# FM33LG0XX register map
File version: 1.0
CPU: SC000 r1p0, little endian, no MPU, no FPU, 3 interrupt priority bits
Registers are 32-bit, read-write, reset 0x0 unless marked. A register's access mark holds for its fields unless they carry their own. Offsets are from the block's base; [hi:lo] are bit positions; {n}, {i} and the like mark numbered series.

## SPI0 — SPI0 module information
Base 0x40010400
Same registers: SPI1 0x40010800, SPI2 0x40014800
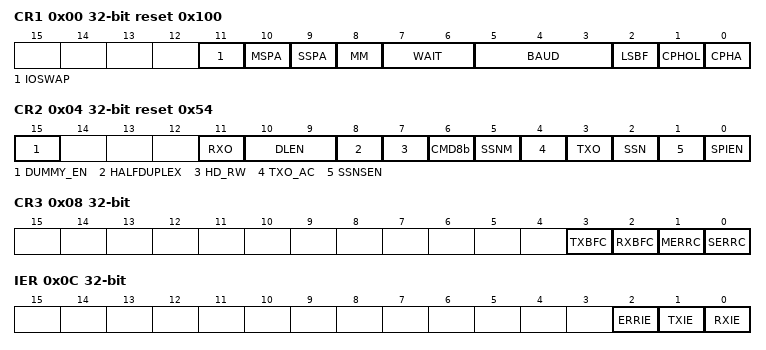
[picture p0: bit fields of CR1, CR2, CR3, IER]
0x00 CR1 reset 0x100 — SPI0Control Register1
  [11] IOSWAP — IOSWAP field description
  [10] MSPA — MSPA field description
  [9] SSPA — SSPA field description
  [8] MM — MM field description
  [7:6] WAIT — WAIT field description
  [5:3] BAUD — BAUD field description
  [2] LSBF — LSBF field description
  [1] CPHOL — CPHOL field description
  [0] CPHA — CPHA field description
0x04 CR2 reset 0x54 — SPI0Control Register2
  [15] DUMMY_EN — DUMMY_EN field description
  [11] RXO — RXO field description
  [10:9] DLEN — DLEN field description
  [8] HALFDUPLEX — HALFDUPLEX field description
  [7] HD_RW — HD_RW field description
  [6] CMD8b — CMD8b field description
  [5] SSNM — SSNM field description
  [4] TXO_AC — TXO_AC field description
  [3] TXO — TXO field description
  [2] SSN — SSN field description
  [1] SSNSEN — SSNSEN field description
  [0] SPIEN — SPIEN field description
0x08 CR3 — SPI0Control Register3
  [3] TXBFC — TXBFC field description
  [2] RXBFC — RXBFC field description
  [1] MERRC — MERRC field description
  [0] SERRC — SERRC field description
0x0C IER — SPI0Interrupt Enable Register
  [2] ERRIE — ERRIE field description
  [1] TXIE — TXIE field description
  [0] RXIE — RXIE field description
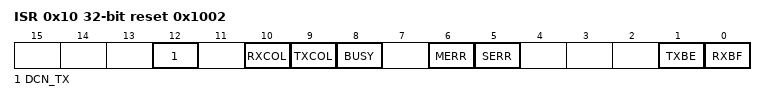
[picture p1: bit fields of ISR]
0x10 ISR access per field reset 0x1002 — SPI0Status Register
  [12] DCN_TX rw — DCN_TX field description
  [10] RXCOL rw — RXCOL field description
  [9] TXCOL rw — TXCOL field description
  [8] BUSY ro — BUSY field description
  [6] MERR ro — MERR field description
  [5] SERR ro — SERR field description
  [1] TXBE ro — TXBE field description
  [0] RXBF ro — RXBF field description
0x14 TXBUF wo — SPI0Transmit Buffer
  [31:0] TXBUF — TXBUF field description
0x18 RXBUF ro — SPI0Receive Buffer
  [31:0] RXBUF — RXBUF field description

## U7816 — U7816 module information
Base 0x40011C00
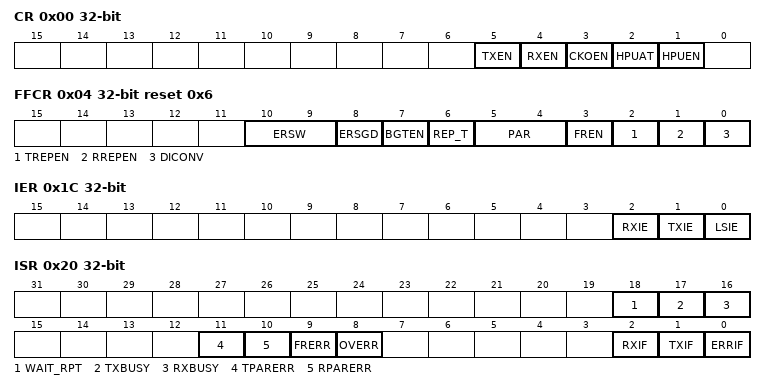
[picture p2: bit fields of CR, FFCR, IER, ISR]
0x00 CR — 7816 Control Register
  [5] TXEN — TXEN field description
  [4] RXEN — RXEN field description
  [3] CKOEN — CKOEN field description
  [2] HPUAT — HPUAT field description
  [1] HPUEN — HPUEN field description
0x04 FFCR reset 0x6 — 7816 Frame Format Control Register
  [10:9] ERSW — ERSW field description
  [8] ERSGD — ERSGD field description
  [7] BGTEN — BGTEN field description
  [6] REP_T — REP_T field description
  [5:4] PAR — PAR field description
  [3] FREN — FREN field description
  [2] TREPEN — TREPEN field description
  [1] RREPEN — RREPEN field description
  [0] DICONV — DICONV field description
0x08 EGTR — 7816 Extra Guard Time Register
  [7:0] TXEGT — TXEGT field description
0x0C CODR reset 0x3 — 7816 Clock Output Divider Register
  [4:0] CLKDIV — CLKDIV field description
0x10 PSCR reset 0x173 — 7816 Prescaler Register
  [11:0] PDIV — PDIV field description
0x14 RXBF — 7816 data RX Buffer
  [7:0] RXBUF — RXBUF field description
0x18 TXBF — 7816 data TX Buffer
  [7:0] TXBUF — TXBUF field description
0x1C IER — 7816 Interrupt Enable Register
  [2] RXIE — RXIE field description
  [1] TXIE — TXIE field description
  [0] LSIE — LSIE field description
0x20 ISR — 7816 Interrupt Status Register
  [18] WAIT_RPT — WAIT_RPT field description
  [17] TXBUSY — TXBUSY field description
  [16] RXBUSY — RXBUSY field description
  [11] TPARERR — TPARERR field description
  [10] RPARERR — RPARERR field description
  [9] FRERR — FRERR field description
  [8] OVERR — OVERR field description
  [2] RXIF — RXIF field description
  [1] TXIF — TXIF field description
  [0] ERRIF — ERRIF field description

## DMA — DMA module information
Base 0x40000400
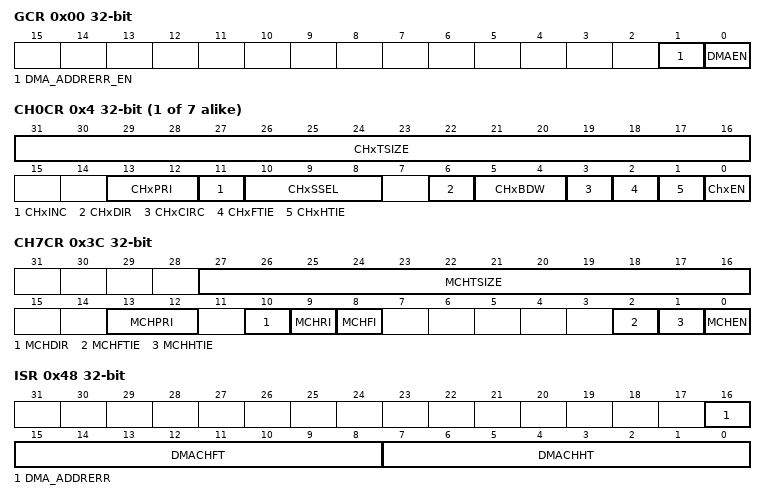
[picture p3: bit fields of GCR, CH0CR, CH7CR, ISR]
0x00 GCR — DMA Global Control Register
  [1] DMA_ADDRERR_EN — DMA_ADDRERR_EN field description
  [0] DMAEN — DMAEN field description
{0x4+8i} CH{i}CR (i=0..6) — Channel {i} Control Register
  [31:16] CHxTSIZE — CHxTSIZE field description
  [13:12] CHxPRI — CHxPRI field description
  [11] CHxINC — CHxINC field description
  [10:8] CHxSSEL — CHxSSEL field description
  [6] CHxDIR — CHxDIR field description
  [5:4] CHxBDW — CHxBDW field description
  [3] CHxCIRC — CHxCIRC field description
  [2] CHxFTIE — CHxFTIE field description
  [1] CHxHTIE — CHxHTIE field description
  [0] ChxEN — ChxEN field description
{0x8+8i} CH{i}MAR (i=0..6) — Channel {i} Memory Address Register
  [31:0] CHxMEMAD — CHxMEMAD field description
0x3C CH7CR — Channel 11 Control Register
  [27:16] MCHTSIZE — MCHTSIZE field description
  [13:12] MCHPRI — MCHPRI field description
  [10] MCHDIR — MCHDIR field description
  [9] MCHRI — MCHRI field description
  [8] MCHFI — MCHFI field description
  [2] MCHFTIE — MCHFTIE field description
  [1] MCHHTIE — MCHHTIE field description
  [0] MCHEN — MCHEN field description
0x40 CH7FAR — Channel 11 Flash Address Register
  [14:0] MCHFLSAD — MCHFLSAD field description
0x44 CH7RAR — Channel 11 RAM Address Register
  [11:0] MCHRAMAD — MCHRAMAD field description
0x48 ISR — DMA Interrupt Status Register
  [16] DMA_ADDRERR — DMA_ADDRERR field description
  [15:8] DMACHFT — DMACHFT field description
  [7:0] DMACHHT — DMACHHT field description
